# M367 register map
File version: 0.1
CPU: 
Registers are 32-bit, read-write, reset 0x0 unless marked. A register's access mark holds for its fields unless they carry their own. Offsets are from the block's base; [hi:lo] are bit positions; {n}, {i} and the like mark numbered series.

## DMAA — DMA Controller
Base 0x4004C000
Same registers: DMAB 0x4004D000
0x00 STATUS ro reset 0x101F0000 — DMA Status Register
  [0] MASTER_ENABLE
0x04 CFG wo reset not defined — DMA Configuration Register
  [0] MASTER_ENABLE
0x08 CTRLBASEPTR — DMA Control Data Base Pointer Register
  [31:10] CTRL_BASE_PTR
0x0C ALTCTRLBASEPTR ro — DMA Channel Alternate Control Data Base Pointer Register
  [31:0] ALT_CTRL_BASE_PTR
0x14 CHNLSWREQUEST wo reset not defined — DMA Channel Software Request Register
  [31:0] CHNL_SW_REQUEST
0x18 CHNLUSEBURSTSET — DMA Channel Useburst Set Register
  [31:0] CHNL_USEBURST_SET
0x1C CHNLUSEBURSTCLR wo reset not defined — DMA Channel Useburst Clear Register
  [31:0] CHNL_USEBURST_CLR
0x20 CHNLREQMASKSET — DMA Channel Request Mask Set Register
  [31:0] CHNL_REQ_MASK_SET
0x24 CHNLREQMASKCLR wo reset not defined — DMA Channel Request Mask Clear Register
  [31:0] CHNL_REQ_MASK_CLR
0x28 CHNLENABLESET — DMA Channel Enable Set Register
  [31:0] CHNL_ENABLE_SET
0x2C CHNLENABLECLR wo reset not defined — DMA Channel Enable Clear Register
  [31:0] CHNL_ENABLE_CLR
0x30 CHNLPRIALTSET — DMA Channel Primary-Alternate Set Register
  [31:0] CHNL_PRI_ALT_SET
0x34 CHNLPRIALTCLR wo reset not defined — DMA Channel Primary-Alternate Clear Register
  [31:0] CHNL_PRI_ALT_CLR
0x38 CHNLPRIORITYSET — DMA Channel Priority Set Register
  [31:0] CHNL_PRIORITY_SET
0x3C CHNLPRIORITYCLR wo reset not defined — DMA Channel Priority Clear Register
  [31:0] CHNL_PRIORITY_CLR
0x4C ERRCLR — DMA Bus Error Clear Register
  [0] ERR_CLR

## ADA — Analog-to-Digital Converter (AD)
Base 0x40050000
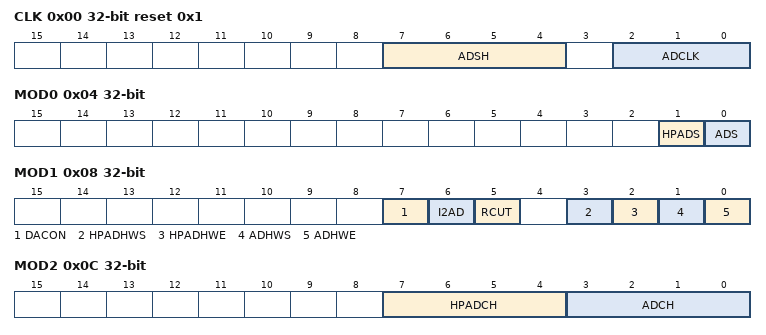
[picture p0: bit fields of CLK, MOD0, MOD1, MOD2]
0x00 CLK reset 0x1 — AD Conversion Clock Setting Register
  [7:4] ADSH, [2:0] ADCLK
0x04 MOD0 wo — AD Mode Control Register 0
  [1] HPADS, [0] ADS
0x08 MOD1 — AD Mode Control Register 1
  [7] DACON, [6] I2AD, [5] RCUT, [3] HPADHWS, [2] HPADHWE, [1] ADHWS, [0] ADHWE
0x0C MOD2 — AD Mode Control Register 2
  [7:4] HPADCH, [3:0] ADCH
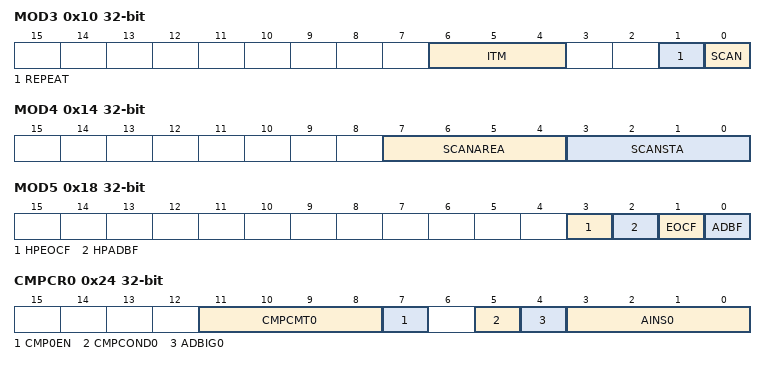
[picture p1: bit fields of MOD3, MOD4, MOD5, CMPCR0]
0x10 MOD3 — AD Mode Control Register 3
  [6:4] ITM, [1] REPEAT, [0] SCAN
0x14 MOD4 — AD Mode Control Register 4
  [7:4] SCANAREA, [3:0] SCANSTA
0x18 MOD5 ro — AD Mode Control Register 5
  [3] HPEOCF, [2] HPADBF, [1] EOCF, [0] ADBF
0x1C MOD6 wo — AD Mode Control Register 6
  [1:0] ADRST
0x24 CMPCR0 — AD Monitoring Setting Register 0
  [11:8] CMPCMT0, [7] CMP0EN, [5] CMPCOND0, [4] ADBIG0, [3:0] AINS0
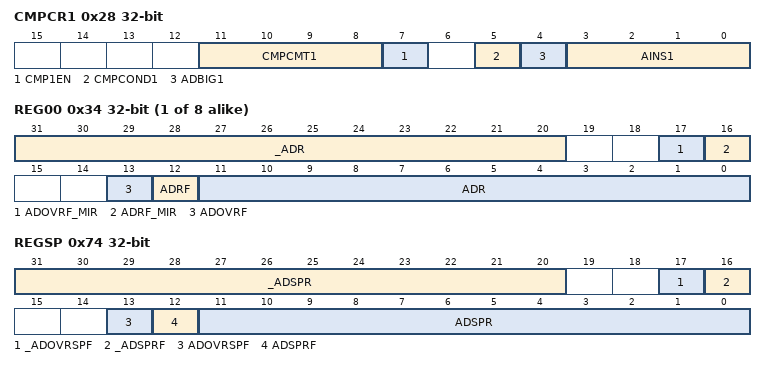
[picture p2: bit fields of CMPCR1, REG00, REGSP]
0x28 CMPCR1 — AD Monitoring Setting Register 1
  [11:8] CMPCMT1, [7] CMP1EN, [5] CMPCOND1, [4] ADBIG1, [3:0] AINS1
0x2C CMP0 — AD Conversion Result Comparison Register 0
  [11:0] AD0CMP
0x30 CMP1 — AD Conversion Result Comparison Register 1
  [11:0] AD1CMP
{0x34+4i} REG{i:02} ro (i=0..7) — AD Conversion Result Register {i:02}
  [31:20] _ADR, [17] ADOVRF_MIR, [16] ADRF_MIR, [13] ADOVRF, [12] ADRF, [11:0] ADR
0x74 REGSP ro — AD Conversion Result Register SP
  [31:20] _ADSPR, [17] _ADOVRSPF, [16] _ADSPRF, [13] ADOVRSPF, [12] ADSPRF, [11:0] ADSPR

## ADB — Analog-to-Digital Converter (AD)
Base 0x40051000
Registers as ADA; these are added or differ:
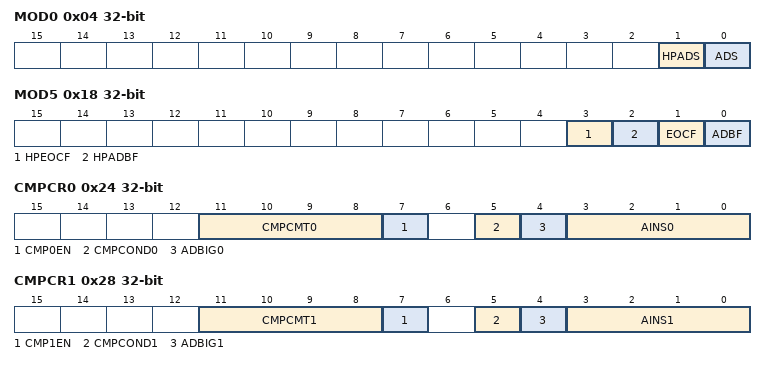
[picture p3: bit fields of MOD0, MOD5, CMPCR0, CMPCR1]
0x04 MOD0 — AD Mode Control Register 0
  [1] HPADS wo, [0] ADS wo
0x18 MOD5 ro — AD Mode Control Register 5
  [3] HPEOCF, [2] HPADBF, [1] EOCF, [0] ADBF
0x1C MOD6 — AD Mode Control Register 6
  [1:0] ADRST wo
0x24 CMPCR0 — AD Monitoring Setting Register 0
  [11:8] CMPCMT0, [7] CMP0EN, [5] CMPCOND0, [4] ADBIG0, [3:0] AINS0
0x28 CMPCR1 — AD Monitoring Setting Register 1
  [11:8] CMPCMT1, [7] CMP1EN, [5] CMPCOND1, [4] ADBIG1, [3:0] AINS1

## ADILV — Dual ADC Configuration
Base 0x40052000
0x00 MO1 wo — Dual Unit Mode Trigger Controller START Register 1
  [7] SWATRG
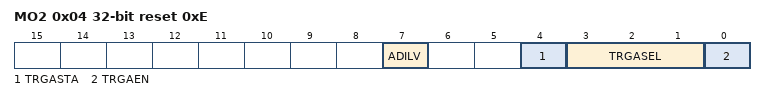
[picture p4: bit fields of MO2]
0x04 MO2 reset 0xE — Dual Unit Mode Trigger Controller START Register 2
  [7] ADILV, [4] TRGASTA ro, [3:1] TRGASEL, [0] TRGAEN
0x08 MO3 reset 0x27 — Dual Unit Mode Trigger Controller START Register 3
  [7:0] CORCNT
